VERSION ""

NS_ :

BS_: 500

BU_: Vector__XXX

BO_ 134 MSG_086: 8 Vector__XXX
 SG_ Steering_Angle : 16|13@1+ (0.1,0) [-720|720] "��" Vector__XXX
 SG_ Steering_Direction : 29|1@1+ (1,0) [0|0] "" Vector__XXX

BO_ 260 MSG_104: 8 Vector__XXX
 SG_ Clutch_Position : 32|8@1+ (0.4,0) [0|0] "" Vector__XXX

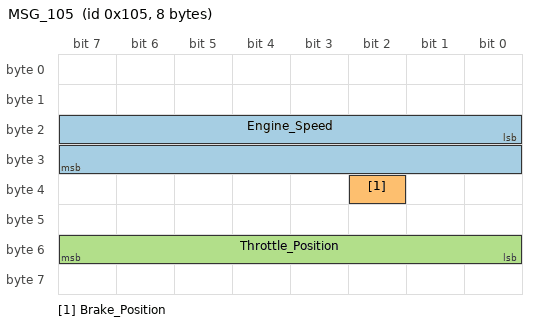
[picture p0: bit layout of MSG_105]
BO_ 261 MSG_105: 8 Vector__XXX
 SG_ Engine_Speed : 16|16@1+ (0.25,0) [0|10000] "rpm" Vector__XXX
 SG_ Brake_Position : 34|1@1+ (1,0) [0|0] "on/off" Vector__XXX
 SG_ Throttle_Position : 48|8@1+ (0.4,0) [0|100] "%" Vector__XXX

BO_ 262 MSG_106: 8 Vector__XXX
 SG_ Brake_Position : 16|11@1+ (1,0) [0|0] "" Vector__XXX

BO_ 776 MSG_308: 8 Vector__XXX
 SG_ Indicated_Vehicle_Speed_kph : 16|16@1+ (0.015,0) [0|0] "km/h" Vector__XXX
 SG_ Indicated_Vehicle_Speed_mph : 16|16@1+ (0.009315,0) [0|0] "mph" Vector__XXX

BO_ 781 MSG_30D: 8 Vector__XXX
 SG_ Handbrake : 2|1@1+ (1,0) [0|0] "on/off" Vector__XXX

BO_ 1634 MSG_662: 8 Vector__XXX
 SG_ Headlights : 17|1@1+ (1,0) [0|0] "on/off" Vector__XXX
 SG_ Full_Beam : 18|1@1+ (1,0) [0|0] "on/off" Vector__XXX
